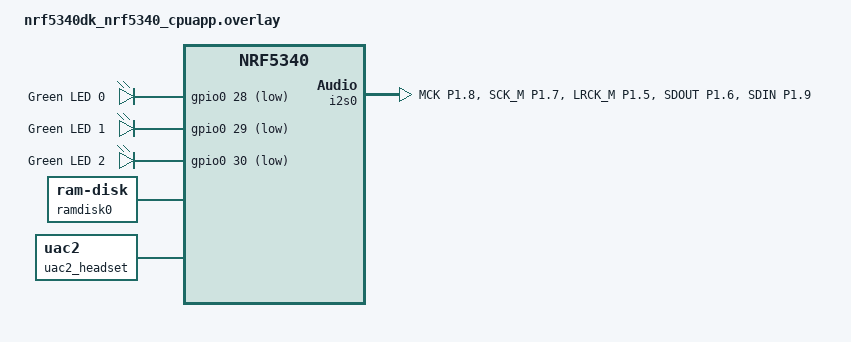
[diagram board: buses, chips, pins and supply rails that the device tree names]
/*
 * Copyright (c) 2024 Nordic Semiconductor ASA
 *
 * SPDX-License-Identifier: LicenseRef-Nordic-5-Clause
 */

 #include <dt-bindings/usb/audio.h>

/ {
	audioleds: audioleds {
		compatible = "gpio-leds";
		status = "okay";

		led_conn_status: led_conn_status {
			gpios = <&gpio0 28 GPIO_ACTIVE_LOW>;
			label = "Green LED 0";
		};

		led_sync_status: led_sync_status {
			gpios = <&gpio0 29 GPIO_ACTIVE_LOW>;
			label = "Green LED 1";
		};

		led_app_status: led_app_status {
			gpios = <&gpio0 30 GPIO_ACTIVE_LOW>;
			label = "Green LED 2";
		};
	};

	ramdisk0: ramdisk0 {
		compatible = "zephyr,ram-disk";
		disk-name = "RAM";
		sector-size = <512>;
		sector-count = <80>;
	};
};

/ {
	uac2_headset: usb_audio2 {
		compatible = "zephyr,uac2";
		status = "okay";
		full-speed;
		audio-function = <AUDIO_FUNCTION_HEADSET>;

		uac_aclk: aclk {
			compatible = "zephyr,uac2-clock-source";
			clock-type = "internal-programmable";
			frequency-control = "read-only";
			sampling-frequencies = <48000>;
			sof-synchronized;
		};

		out_terminal: out_terminal {
			compatible = "zephyr,uac2-input-terminal";
			clock-source = <&uac_aclk>;
			terminal-type = <USB_TERMINAL_STREAMING>;
			front-left;
			front-right;
		};

		headphones_output: headphones {
			compatible = "zephyr,uac2-output-terminal";
			data-source = <&out_terminal>;
			clock-source = <&uac_aclk>;
			terminal-type = <BIDIRECTIONAL_TERMINAL_HEADSET>;
			assoc-terminal = <&mic_input>;
		};

		in_terminal: in_terminal {
			compatible = "zephyr,uac2-output-terminal";
			data-source = <&mic_input>;
			clock-source = <&uac_aclk>;
			terminal-type = <USB_TERMINAL_STREAMING>;
		};

		mic_input: microphone {
			compatible = "zephyr,uac2-input-terminal";
			clock-source = <&uac_aclk>;
			terminal-type = <BIDIRECTIONAL_TERMINAL_HEADSET>;
			front-left;
			front-right;
		};

		as_iso_out: out_interface {
			compatible = "zephyr,uac2-audio-streaming";
			linked-terminal = <&out_terminal>;
			subslot-size = <2>;
			bit-resolution = <16>;
		};

		as_iso_in: in_interface {
			compatible = "zephyr,uac2-audio-streaming";
			linked-terminal = <&in_terminal>;
			subslot-size = <2>;
			bit-resolution = <16>;
		};
	};
};

/ {
	uac2_headphones: usb_audio2 {
		compatible = "zephyr,uac2";
		status = "okay";
		full-speed;
		audio-function = <AUDIO_FUNCTION_OTHER>;

		hp_uac_aclk: hp_aclk {
			compatible = "zephyr,uac2-clock-source";
			clock-type = "internal-programmable";
			frequency-control = "read-only";
			sampling-frequencies = <48000>;
			sof-synchronized;
		};

		hp_out_terminal: out_terminal {
			compatible = "zephyr,uac2-input-terminal";
			clock-source = <&hp_uac_aclk>;
			terminal-type = <USB_TERMINAL_STREAMING>;
			front-left;
			front-right;
		};

		hp_headphones_output: hp_headphones_output {
			compatible = "zephyr,uac2-output-terminal";
			data-source = <&hp_out_terminal>;
			clock-source = <&hp_uac_aclk>;
			terminal-type = <OUTPUT_TERMINAL_HEADPHONES>;
		};

		hp_as_iso_out: out_interface {
			compatible = "zephyr,uac2-audio-streaming";
			linked-terminal = <&hp_out_terminal>;
			subslot-size = <2>;
			bit-resolution = <16>;
		};
	};
};

&pinctrl {
	i2s0_default: i2s0_default {
		group1 {
			psels = <NRF_PSEL(I2S_MCK, 1, 8)>;
			nordic,drive-mode = <NRF_DRIVE_H0H1>;
		};

		group2 {
			psels = <NRF_PSEL(I2S_SCK_M, 1, 7)>,
			<NRF_PSEL(I2S_LRCK_M, 1, 5)>,
			<NRF_PSEL(I2S_SDOUT, 1, 6)>,
			<NRF_PSEL(I2S_SDIN, 1, 9)>;
		};
	};

	i2s0_sleep: i2s0_sleep {
		group1 {
			psels = <NRF_PSEL(I2S_MCK, 1, 8)>,
			<NRF_PSEL(I2S_SCK_M, 1, 7)>,
			<NRF_PSEL(I2S_LRCK_M, 1, 5)>,
			<NRF_PSEL(I2S_SDOUT, 1, 6)>,
			<NRF_PSEL(I2S_SDIN, 1, 9)>;
			low-power-enable;
		};
	};
};

&i2s0 {
	compatible = "nordic,nrf-i2s";
	status = "okay";
	pinctrl-0 = <&i2s0_default>;
	pinctrl-1 = <&i2s0_sleep>;
	pinctrl-names = "default", "sleep";
};
